# FLASH_CTRL register map
Vendor: Texas Instruments
Peripheral module from a debugger description file (folder cc2538).
Registers are 32-bit, read-only, no defined reset value unless marked. A register's access mark holds for its fields unless they carry their own. Offsets are as the file gives them; lines under a group give offsets from that group; [hi:lo] are bit positions; {n}, {i} and the like mark numbered series; 'fields as' and 'values as' point back to an identical list; <NAME> marks a mode.

## FLASH_CTRL — Register fields should be considered static unless otherwise noted as dynamic.
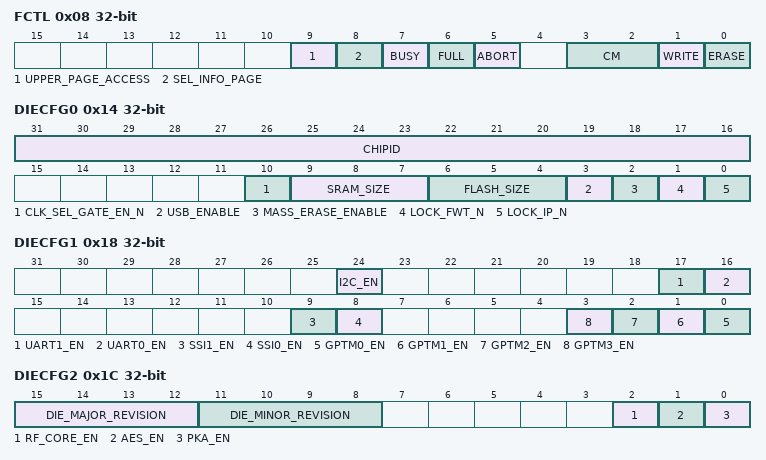
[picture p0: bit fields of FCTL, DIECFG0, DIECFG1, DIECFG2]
0x08 FCTL access per field — Flash control This register provides control and monitoring functions for the flash module.
  [9] UPPER_PAGE_ACCESS rw — Lock bit for lock bit page 0: Neither write nor erase not allowed 1: Both write and erase allowed
  [8] SEL_INFO_PAGE rw — Flash erase or write operation on APB bus must assert this when accessing the information page
  [7] BUSY ro — Set when the WRITE or ERASE bit is set; that is, when the flash controller is busy
  [6] FULL ro — Write buffer full The CPU can write to FWDATA when this bit is 0 and WRITE is 1. This bit is cleared when BUSY is cleared.
  [5] ABORT ro — Abort status This bit is set to 1 when a write sequence or page erase is aborted. An operation is aborted when the accessed page is locked. Cleared when a write or page erase is started. If a write operation times out (because the FWDATA register is not written fast enough), the ABORT bit is not set even if the page is locked. If a page erase and a write operation are started simultaneously, the ABORT bit reflects the status of the last write operation. For example, if the page is locked and the write times out, the ABORT bit is not set because only the write operation times out.
  [3:2] CM rw — Cache Mode Disabling the cache increases the power consumption and reduces performance. Prefetching improves performance at the expense of a potential increase in power consumption. Real-time mode provides predictable flash read access time, the execution time is equal to cache disabled mode, but the power consumption is lower. 00: Cache disabled 01: Cache enabled 10: Cache enabled, with prefetch 11: Real-time mode Note: The read value always represents the current cache mode. Writing a new cache mode starts a cache mode change request that does not take effect until the controller is ready. Writes to this register are ignored if there is a current cache change request in progress.
  [1] WRITE rw — Write bit Start a write sequence by setting this bit to 1. Cleared by hardware when the operation completes. Writes to this bit are ignored when FCTL.BUSY is 1. If FCTL.ERASE is set simultaneously with this bit, the erase operation is started first, then the write is started.
  [0] ERASE rw — Erase bit Start an erase operation by setting this bit to 1. Cleared by hardware when the operation completes. Writes to this bit are ignored when FCTL.BUSY is 1. If FCTL.WRITE is set simultaneously with this bit, the erase operation is started first, then the write is started.
0x0C FADDR access per field — Flash address The register sets the address to be written in flash memory. See the bitfield descriptions for formatting information.
  [16:0] FADDR rw — Bit number [16:9] selects one of 256 pages for page erase. Bit number [8:7] selects one of the 4 row in a given page Bit number [6:1] selects one of the 64-bit wide locations in a give row. Bit number [0] will select upper/lower 32-bits in a given 64-bit location - 64Kbytes --> Bits [16:14] will always be 0. - 128Kbytes --> Bits [16:15] will always be 0. - 256Kbytes --> Bit [16] will always be 0. - 384/512Kbytes --> All bits written and valid. Writes to this register will be ignored when any of FCTL.WRITE and FCTL.ERASE is set. FADDR should be written with byte addressable location of the Flash to be programmed. Read back value always reflects a 32-bit aligned address. When the register is read back, the value that was written to FADDR gets right shift by 2 to indicate 32-bit aligned address. In other words lower 2 bits are discarded while reading back the register. Out of range address results in roll over. There is no status signal generated by flash controller to indicate this. Firmware is responsible to managing the addresses correctly.
0x10 FWDATA rw — Flash data This register contains the 32-bits of data to be written to the flash location selected in FADDR.
  [31:0] FWDATA — 32-bit flash write data Writes to this register are accepted only during a flash write sequence; that is, writes to this register after having written 1 to the FCTL.WRITE bit. New 32-bit data is written only if FCTL.FULL = 0.
0x14 DIECFG0 — These settings are a function of the FLASH information page bit settings, which are programmed during production test, and are subject for specific configuration for multiple device flavors of cc2538.
  [31:16] CHIPID — Register copy of configuration bits Three clock cycles after reset is released, this bit field is equal to the field with the same name in the information page.
  [10] CLK_SEL_GATE_EN_N — Register copy of configuration bits Three clock cycles after reset is released, this bit is equal to the field with the same name in the information page.
  [9:7] SRAM_SIZE — Register copy of configuration bits Three clock cycles after reset is released, this bit field is equal to the field with the same name in the information page.
  [6:4] FLASH_SIZE — Register copy of configuration bits Three clock cycles after reset is released, this bit field is equal to the field with the same name in the information page.
  [3] USB_ENABLE — Register copy of configuration bits Three clock cycles after reset is released, this bit is equal to the field with the same name in the information page.
  [2] MASS_ERASE_ENABLE — Register copy of configuration bits Three clock cycles after reset is released, this bit is equal to the field with the same name in the information page.
  [1] LOCK_FWT_N — Register copy of configuration bits Three clock cycles after reset is released, this bit is equal to the field with the same name in the information page.
  [0] LOCK_IP_N — Register copy of configuration bits Three clock cycles after reset is released, this bit is equal to the field with the same name in the information page.
0x18 DIECFG1 — These settings are a function of the FLASH information page bit settings, which are programmed during production test, and are subject for specific configuration for multiple device flavors of cc2538.
  [24] I2C_EN — 1: I2C is enabled. 0: I2C is permanently disabled.
  [17] UART1_EN — 1: UART1 is enabled. 0: UART1 is permanently disabled.
  [16] UART0_EN — 1: UART0 is enabled. 0: UART0 is permanently disabled.
  [9] SSI1_EN — 1: SSI1 is enabled. 0: SSI1 is permanently disabled.
  [8] SSI0_EN — 1: SSI0 is enabled. 0: SSI0 is permanently disabled.
  [n] GPTM{n}_EN (n=0..3) — 1: GPTM{n} is enabled. 0: GPTM{n} is permanently disabled.
0x1C DIECFG2 — These settings are a function of the FLASH information page bit settings, which are programmed during production test, and are subject for specific configuration for multiple device flavors of cc2538. The DIE_*_REVISION registers are an exeception to this, as they are hardwired and are not part of the FLASH information page.
  [15:12] DIE_MAJOR_REVISION — Indicates the major revision (all layer change) number for the cc2538 0x0 - PG1.0 0x2 - PG2.0
  [11:8] DIE_MINOR_REVISION — Indicates the minor revision (metla layer only) number for the cc2538 0x0 - PG1.0 or PG2.0
  [2] RF_CORE_EN — 1: RF_CORE is enabled. 0: RF_CORE is permanently disabled.
  [1] AES_EN — 1: AES is enabled. 0: AES is permanently disabled.
  [0] PKA_EN — 1: PKA is enabled. 0: PKA is permanently disabled.
